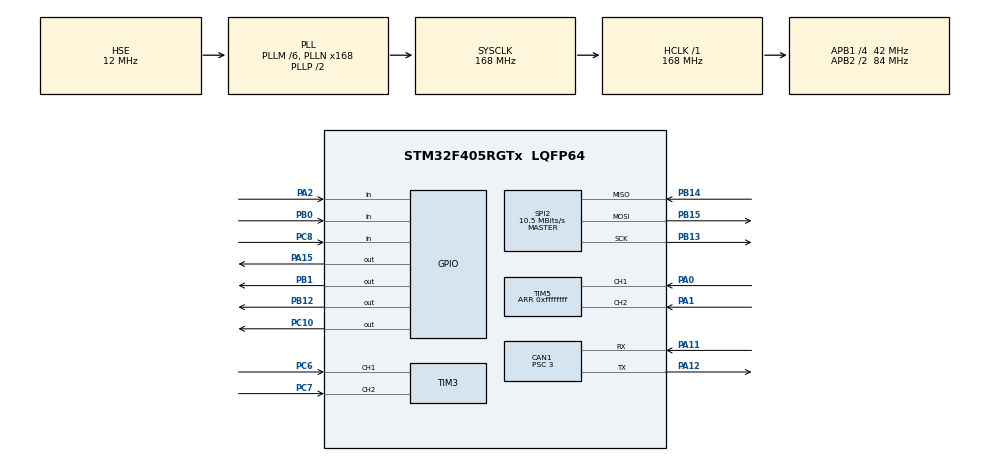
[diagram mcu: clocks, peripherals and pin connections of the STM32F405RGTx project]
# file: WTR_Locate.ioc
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CAN1.BS1=CAN_BS1_9TQ
CAN1.BS2=CAN_BS2_4TQ
CAN1.CalculateTimeQuantum=71.42857142857143
CAN1.Prescaler=3
Mcu.Family=STM32F4
Mcu.Name=STM32F405RGTx
Mcu.Package=LQFP64
NVIC.CAN1_TX_IRQn=true\:0\:0\:false\:false\:true\:true\:true
NVIC.PriorityGroup=NVIC_PRIORITYGROUP_4
PA0-WKUP.Signal=S_TIM5_CH1
PA1.Signal=S_TIM5_CH2
PA11.Mode=Master
PA11.Signal=CAN1_RX
PA12.Mode=Master
PA12.Signal=CAN1_TX
PA13.Mode=Serial_Wire
PA13.Signal=SYS_JTMS-SWDIO
PA14.Mode=Serial_Wire
PA14.Signal=SYS_JTCK-SWCLK
PA15.GPIO_PuPd=GPIO_PULLUP
PA15.GPIO_Speed=GPIO_SPEED_FREQ_LOW
PA15.Signal=GPIO_Output
PA2.GPIO_PuPd=GPIO_PULLDOWN
PA2.Signal=GPIO_Input
PB0.GPIO_PuPd=GPIO_PULLUP
PB0.Signal=GPIO_Input
PB1.GPIO_PuPd=GPIO_PULLUP
PB1.PinState=GPIO_PIN_SET
PB1.Signal=GPIO_Output
PB12.GPIO_PuPd=GPIO_PULLUP
PB12.GPIO_Speed=GPIO_SPEED_FREQ_VERY_HIGH
PB12.PinState=GPIO_PIN_SET
PB12.Signal=GPIO_Output
PB13.Mode=Full_Duplex_Master
PB13.Signal=SPI2_SCK
PB14.Mode=Full_Duplex_Master
PB14.Signal=SPI2_MISO
PB15.Mode=Full_Duplex_Master
PB15.Signal=SPI2_MOSI
PC10.GPIO_PuPd=GPIO_PULLUP
PC10.GPIO_Speed=GPIO_SPEED_FREQ_LOW
PC10.Signal=GPIO_Output
PC6.Signal=S_TIM3_CH1
PC7.Signal=S_TIM3_CH2
PC8.GPIO_PuPd=GPIO_PULLDOWN
PC8.Signal=GPIO_Input
PH0-OSC_IN.Mode=HSE-External-Oscillator
PH0-OSC_IN.Signal=RCC_OSC_IN
PH1-OSC_OUT.Mode=HSE-External-Oscillator
PH1-OSC_OUT.Signal=RCC_OSC_OUT
ProjectManager.HeapSize=0x200
ProjectManager.StackSize=0x400
ProjectManager.TargetToolchain=MDK-ARM V5.27
RCC.48MHZClocksFreq_Value=84000000
RCC.AHBFreq_Value=168000000
RCC.APB1CLKDivider=RCC_HCLK_DIV4
RCC.APB1Freq_Value=42000000
RCC.APB1TimFreq_Value=84000000
RCC.APB2CLKDivider=RCC_HCLK_DIV2
RCC.APB2Freq_Value=84000000
RCC.APB2TimFreq_Value=168000000
RCC.CortexFreq_Value=168000000
RCC.HCLKFreq_Value=168000000
RCC.HSE_VALUE=12000000
RCC.HSI_VALUE=16000000
RCC.LSE_VALUE=32768
RCC.PLLM=6
RCC.PLLN=168
RCC.PLLSourceVirtual=RCC_PLLSOURCE_HSE
RCC.SYSCLKFreq_VALUE=168000000
RCC.SYSCLKSource=RCC_SYSCLKSOURCE_PLLCLK
RCC.VCOOutputFreq_Value=336000000
SH.S_TIM3_CH1.0=TIM3_CH1,Encoder_Interface
SH.S_TIM3_CH2.0=TIM3_CH2,Encoder_Interface
SH.S_TIM5_CH1.0=TIM5_CH1,Encoder_Interface
SH.S_TIM5_CH2.0=TIM5_CH2,Encoder_Interface
SPI2.BaudRatePrescaler=SPI_BAUDRATEPRESCALER_4
SPI2.CLKPhase=SPI_PHASE_2EDGE
SPI2.CalculateBaudRate=10.5 MBits/s
SPI2.DataSize=SPI_DATASIZE_16BIT
SPI2.Direction=SPI_DIRECTION_2LINES
SPI2.Mode=SPI_MODE_MASTER
SPI2.VirtualType=VM_MASTER
TIM3.EncoderMode=TIM_ENCODERMODE_TI12
TIM5.EncoderMode=TIM_ENCODERMODE_TI12
TIM5.Period=0xffffffff
board=custom

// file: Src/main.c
/* USER CODE BEGIN Header */
/**
  ******************************************************************************
  * @file           : main.c
  * @brief          : Main program body
  ******************************************************************************
  * @attention
  *
  * <h2><center>&copy; Copyright (c) 2020 STMicroelectronics.
  * All rights reserved.</center></h2>
  *
  * This software component is licensed by ST under BSD 3-Clause license,
  * the "License"; You may not use this file except in compliance with the
  * License. You may obtain a copy of the License at:
  *                        opensource.org/licenses/BSD-3-Clause
  *
  ******************************************************************************
  */
/* USER CODE END Header */

#include "main.h"
#include "can.h"
#include "spi.h"
#include "tim.h"
#include "gpio.h"

/* USER CODE BEGIN Includes */

#include "CanOperation.h"
#include "InitAll.h"
#include "Calculate.h"

/* USER CODE END Includes */

void SystemClock_Config(void);

int main(void)
{

  /* MCU Configuration--------------------------------------------------------*/

  /* Reset of all peripherals, Initializes the Flash interface and the Systick. */
  HAL_Init();

  /* Configure the system clock */
  SystemClock_Config();

  /* Initialize all configured peripherals */
  MX_GPIO_Init();
  MX_CAN1_Init();
  MX_SPI2_Init();
  MX_TIM3_Init();
  MX_TIM5_Init();
  /* USER CODE BEGIN 2 */
	InitAll();

  /* USER CODE END 2 */

  /* Infinite loop */
  /* USER CODE BEGIN WHILE */
  while (1)
  {
		ReportResult();
		delay_ms(1);
    /* USER CODE END WHILE */

  }
}

void SystemClock_Config(void)
{
  RCC_OscInitTypeDef RCC_OscInitStruct = {0};
  RCC_ClkInitTypeDef RCC_ClkInitStruct = {0};

  /** Configure the main internal regulator output voltage
  */
  __HAL_RCC_PWR_CLK_ENABLE();
  __HAL_PWR_VOLTAGESCALING_CONFIG(PWR_REGULATOR_VOLTAGE_SCALE1);
  /** Initializes the CPU, AHB and APB busses clocks
  */
  RCC_OscInitStruct.OscillatorType = RCC_OSCILLATORTYPE_HSE;
  RCC_OscInitStruct.HSEState = RCC_HSE_ON;
  RCC_OscInitStruct.PLL.PLLState = RCC_PLL_ON;
  RCC_OscInitStruct.PLL.PLLSource = RCC_PLLSOURCE_HSE;
  RCC_OscInitStruct.PLL.PLLM = 6;
  RCC_OscInitStruct.PLL.PLLN = 168;
  RCC_OscInitStruct.PLL.PLLP = RCC_PLLP_DIV2;
  RCC_OscInitStruct.PLL.PLLQ = 4;
  if (HAL_RCC_OscConfig(&RCC_OscInitStruct) != HAL_OK)
  {
    Error_Handler();
  }
  /** Initializes the CPU, AHB and APB busses clocks
  */
  RCC_ClkInitStruct.ClockType = RCC_CLOCKTYPE_HCLK|RCC_CLOCKTYPE_SYSCLK
                              |RCC_CLOCKTYPE_PCLK1|RCC_CLOCKTYPE_PCLK2;
  RCC_ClkInitStruct.SYSCLKSource = RCC_SYSCLKSOURCE_PLLCLK;
  RCC_ClkInitStruct.AHBCLKDivider = RCC_SYSCLK_DIV1;
  RCC_ClkInitStruct.APB1CLKDivider = RCC_HCLK_DIV4;
  RCC_ClkInitStruct.APB2CLKDivider = RCC_HCLK_DIV2;

  if (HAL_RCC_ClockConfig(&RCC_ClkInitStruct, FLASH_LATENCY_5) != HAL_OK)
  {
    Error_Handler();
  }
}

void Error_Handler(void)
{
  /* USER CODE BEGIN Error_Handler_Debug */
  /* User can add his own implementation to report the HAL error return state */
	while(1)
	{
		HAL_GPIO_TogglePin(GPIOA,GPIO_PIN_15);
	  delay_ms(500);
  }
  /* USER CODE END Error_Handler_Debug */
}

/************************ (C) COPYRIGHT STMicroelectronics *****END OF FILE****/
